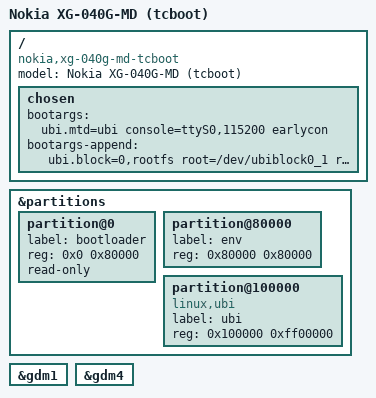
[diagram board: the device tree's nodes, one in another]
// SPDX-License-Identifier: GPL-2.0-only OR MIT

#include "an7581-nokia_xg-040g-md-common.dtsi"

/ {
	model = "Nokia XG-040G-MD (tcboot)";
	compatible = "nokia,xg-040g-md-tcboot", "airoha,an7581",
		     "airoha,en7581";

	chosen {
		bootargs = "ubi.mtd=ubi console=ttyS0,115200 earlycon";
		/* Keep the SquashFS block mapping when U-Boot replaces bootargs. */
		bootargs-append = " ubi.block=0,rootfs root=/dev/ubiblock0_1 rootfstype=squashfs ro rootwait";
	};
};

&partitions {
	partition@0 {
		label = "bootloader";
		reg = <0x0 0x80000>;
		read-only;
	};

	partition@80000 {
		label = "env";
		reg = <0x80000 0x80000>;
	};

	partition@100000 {
		label = "ubi";
		reg = <0x100000 0xff00000>;
		compatible = "linux,ubi";
	};
};

&gdm1 {
	/delete-property/ nvmem-cell-names;
	/delete-property/ nvmem-cells;
};

&gdm4 {
	/delete-property/ nvmem-cell-names;
	/delete-property/ nvmem-cells;
};
